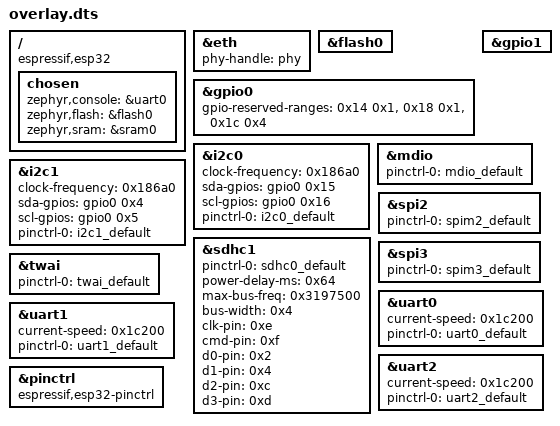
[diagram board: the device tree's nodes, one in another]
/ {
	compatible = "espressif,esp32";
	chosen {
		zephyr,console = &uart0;
		zephyr,flash = &flash0;
		zephyr,sram = &sram0;
	};
};
&eth{
	phy-handle = < &phy >;
};
&flash0{
	status = "okay";
};
&gpio0{
	gpio-reserved-ranges = < 0x14 0x1 >, < 0x18 0x1 >, < 0x1c 0x4 >;
};
&gpio1{
	status = "okay";
};
&i2c0{
	status = "okay";
	clock-frequency = < 0x186a0 >;
	sda-gpios = < &gpio0 0x15 0x6 >;
	scl-gpios = < &gpio0 0x16 0x6 >;
	pinctrl-0 = < &i2c0_default >;
	pinctrl-names = "default";
};
&i2c1{
	status = "okay";
	clock-frequency = < 0x186a0 >;
	sda-gpios = < &gpio0 0x4 0x6 >;
	scl-gpios = < &gpio0 0x5 0x6 >;
	pinctrl-0 = < &i2c1_default >;
	pinctrl-names = "default";
};
&mdio{
	pinctrl-0 = < &mdio_default >;
	pinctrl-names = "default";
};
&sdhc1{
	status = "okay";
	pinctrl-0 = < &sdhc0_default >;
	pinctrl-names = "default";
	power-delay-ms = < 0x64 >;
	max-bus-freq = < 0x3197500 >;
	bus-width = < 0x4 >;
	clk-pin = < 0xe >;
	cmd-pin = < 0xf >;
	d0-pin = < 0x2 >;
	d1-pin = < 0x4 >;
	d2-pin = < 0xc >;
	d3-pin = < 0xd >;
};
&spi2{
	status = "okay";
	#address-cells = < 0x1 >;
	#size-cells = < 0x0 >;
	pinctrl-0 = < &spim2_default >;
	pinctrl-names = "default";
};
&spi3{
	status = "okay";
	#address-cells = < 0x1 >;
	#size-cells = < 0x0 >;
	pinctrl-0 = < &spim3_default >;
	pinctrl-names = "default";
};
&twai{
	status = "okay";
	pinctrl-0 = < &twai_default >;
	pinctrl-names = "default";
};
&uart0{
	status = "okay";
	current-speed = < 0x1c200 >;
	pinctrl-0 = < &uart0_default >;
	pinctrl-names = "default";
};
&uart1{
	current-speed = < 0x1c200 >;
	pinctrl-0 = < &uart1_default >;
	pinctrl-names = "default";
};
&uart2{
	current-speed = < 0x1c200 >;
	pinctrl-0 = < &uart2_default >;
	pinctrl-names = "default";
};
&pinctrl{
	compatible = "espressif,esp32-pinctrl";
	status = "okay";
};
